# ATSAML10E16A device description
Architecture: CORTEX-M23; Family: SAML; Series: SAML10
Registers are 32-bit, read-write, reset 0x0 unless marked. A register's access mark holds for its fields unless they carry their own. Offsets are from the block's base; [hi:lo] are bit positions; {n}, {i} and the like mark numbered series; 'fields as' and 'values as' point back to an identical list; <NAME> marks a mode.

## TC — Basic Timer Counter
Instances: TC0 0x42001000, TC1 0x42001400, TC2 0x42001800
Modes: COUNT8 when TC.CTRLA.MODE=1 (8-bit Counter Mode); COUNT16 when TC.CTRLA.MODE=0 (16-bit Counter Mode); COUNT32 when TC.CTRLA.MODE=2 (32-bit Counter Mode)
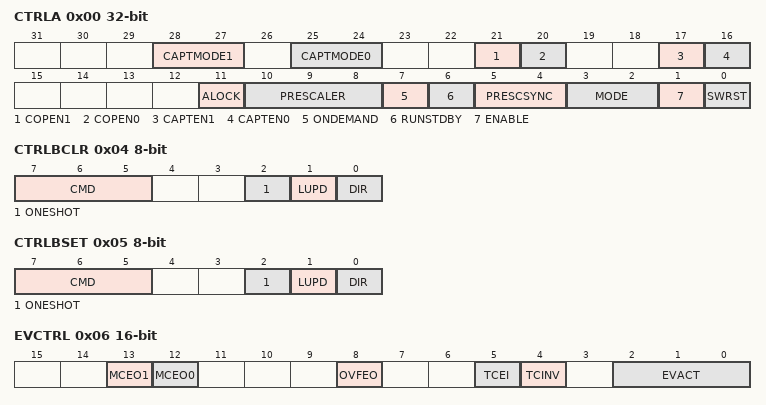
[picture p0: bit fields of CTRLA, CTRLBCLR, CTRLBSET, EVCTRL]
0x00 CTRLA — Control A
  [28:27] CAPTMODE1 — Capture mode Channel 1
    0=DEFAULT (Default capture); 1=CAPTMIN (Minimum capture); 2=CAPTMAX (Maximum capture)
  [25:24] CAPTMODE0 — Capture Mode Channel 0
    values as CAPTMODE1
  [21] COPEN1 — Capture On Pin 1 Enable
  [20] COPEN0 — Capture On Pin 0 Enable
  [17] CAPTEN1 — Capture Channel 1 Enable
  [16] CAPTEN0 — Capture Channel 0 Enable
  [11] ALOCK — Auto Lock
  [10:8] PRESCALER
    0=DIV1 (Prescaler: GCLK_TC); 1=DIV2 (Prescaler: GCLK_TC/2); 2=DIV4 (Prescaler: GCLK_TC/4); 3=DIV8 (Prescaler: GCLK_TC/8); 4=DIV16 (Prescaler: GCLK_TC/16); 5=DIV64 (Prescaler: GCLK_TC/64); 6=DIV256 (Prescaler: GCLK_TC/256); 7=DIV1024 (Prescaler: GCLK_TC/1024)
  [7] ONDEMAND — Clock On Demand
  [6] RUNSTDBY — Run during Standby
  [5:4] PRESCSYNC — Prescaler and Counter Synchronization
    0=GCLK (Reload or reset the counter on next generic clock); 1=PRESC (Reload or reset the counter on next prescaler clock); 2=RESYNC (Reload or reset the counter on next generic clock and reset the prescaler counter)
  [3:2] MODE — Timer Counter Mode
    0=COUNT16 (Counter in 16-bit mode); 1=COUNT8 (Counter in 8-bit mode); 2=COUNT32 (Counter in 32-bit mode)
  [1] ENABLE
  [0] SWRST — Software Reset
0x04 CTRLBCLR 8-bit (atomic clear) (RWSYNC) — Control B Clear
  [7:5] CMD — Command
  [2] ONESHOT — One-Shot on Counter
  [1] LUPD — Lock Update
  [0] DIR — Counter Direction
0x05 CTRLBSET 8-bit (atomic set) (RWSYNC) — Control B Set
  [7:5] CMD — Command
    0=NONE (No action); 1=RETRIGGER (Force a start, restart or retrigger); 2=STOP (Force a stop); 3=UPDATE (Force update of double-buffered register); 4=READSYNC (Force a read synchronization of COUNT)
  [2] ONESHOT — One-Shot on Counter
  [1] LUPD — Lock Update
  [0] DIR — Counter Direction
0x06 EVCTRL 16-bit — Event Control
  [13] MCEO1 — MC Event Output Enable 1
  [12] MCEO0 — MC Event Output Enable 0
  [8] OVFEO — Event Output Enable
  [5] TCEI — TC Event Enable
  [4] TCINV — TC Event Input Polarity
  [2:0] EVACT — Event Action
    0=OFF (Event action disabled); 1=RETRIGGER (Start, restart or retrigger TC on event); 2=COUNT (Count on event); 3=START (Start TC on event); 4=STAMP (Time stamp capture); 5=PPW (Period catured in CC0, pulse width in CC1); 6=PWP (Period catured in CC1, pulse width in CC0); 7=PW (Pulse width capture)
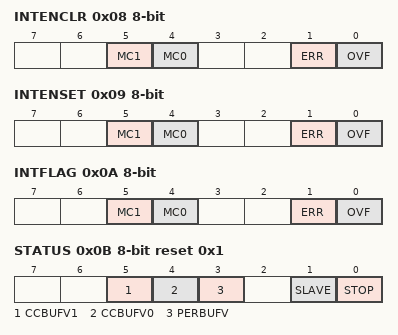
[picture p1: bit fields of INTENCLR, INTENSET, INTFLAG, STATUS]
0x08 INTENCLR 8-bit (atomic clear) — Interrupt Enable Clear
  [5] MC1 — MC Interrupt Disable 1
  [4] MC0 — MC Interrupt Disable 0
  [1] ERR — ERR Interrupt Disable
  [0] OVF — OVF Interrupt Disable
0x09 INTENSET 8-bit (atomic set) — Interrupt Enable Set
  [5] MC1 — MC Interrupt Enable 1
  [4] MC0 — MC Interrupt Enable 0
  [1] ERR — ERR Interrupt Enable
  [0] OVF — OVF Interrupt Enable
0x0A INTFLAG 8-bit (atomic clear) — Interrupt Flag Status and Clear
  [5] MC1 — MC Interrupt Flag 1
  [4] MC0 — MC Interrupt Flag 0
  [1] ERR — ERR Interrupt Flag
  [0] OVF — OVF Interrupt Flag
0x0B STATUS 8-bit reset 0x1 (RSYNC)
  [5] CCBUFV1 — Compare channel buffer 1 valid
  [4] CCBUFV0 — Compare channel buffer 0 valid
  [3] PERBUFV — Synchronization Busy Status
  [1] SLAVE — Slave Status Flag
  [0] STOP — Stop Status Flag
0x0C WAVE 8-bit — Waveform Generation Control
  [1:0] WAVEGEN — Waveform Generation Mode
    0=NFRQ (Normal frequency); 1=MFRQ (Match frequency); 2=NPWM (Normal PWM); 3=MPWM (Match PWM)
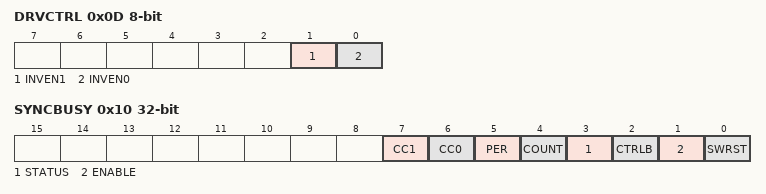
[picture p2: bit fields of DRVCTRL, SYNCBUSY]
0x0D DRVCTRL 8-bit — Control C
  [1] INVEN1 — Output Waveform Invert Enable 1
  [0] INVEN0 — Output Waveform Invert Enable 0
0x0F DBGCTRL 8-bit — Debug Control
  [0] DBGRUN — Run During Debug
0x10 SYNCBUSY ro — Synchronization Status
  [7] CC1 — Compare Channel 1
  [6] CC0 — Compare Channel 0
  [5] PER — Period
  [4] COUNT — Counter
  [3] STATUS
  [2] CTRLB
  [1] ENABLE
  [0] SWRST
0x14 COUNT <COUNT16> 16-bit (RWSYNC) — COUNT16 Count
  [15:0] COUNT — Counter Value
0x1A PER <COUNT16> 16-bit reset 0xFFFF (WSYNC) — COUNT16 Period
  [15:0] PER — Period Value
{0x1C+2i} CC[{i}] (i=0..1) <COUNT16> 16-bit (RWSYNC) — COUNT16 Compare and Capture
  [15:0] CC — Counter/Compare Value
0x2E PERBUF <COUNT16> 16-bit reset 0xFFFF (WSYNC) — COUNT16 Period Buffer
  [15:0] PERBUF — Period Buffer Value
{0x30+2i} CCBUF[{i}] (i=0..1) <COUNT16> 16-bit (WSYNC) — COUNT16 Compare and Capture Buffer
  [15:0] CCBUF — Counter/Compare Buffer Value
0x14 COUNT <COUNT32> (RWSYNC) — COUNT32 Count
  [31:0] COUNT — Counter Value
0x18 PER <COUNT32> reset 0xFFFFFFFF (WSYNC) — COUNT32 Period
  [31:0] PER — Period Value
{0x1C+4i} CC[{i}] (i=0..1) <COUNT32> (WSYNC) — COUNT32 Compare and Capture
  [31:0] CC — Counter/Compare Value
0x2C PERBUF <COUNT32> reset 0xFFFFFFFF (WSYNC) — COUNT32 Period Buffer
  [31:0] PERBUF — Period Buffer Value
{0x30+4i} CCBUF[{i}] (i=0..1) <COUNT32> (WSYNC) — COUNT32 Compare and Capture Buffer
  [31:0] CCBUF — Counter/Compare Buffer Value
0x14 COUNT <COUNT8> 8-bit (RWSYNC) — COUNT8 Count
  [7:0] COUNT — Counter Value
0x1B PER <COUNT8> 8-bit reset 0xFF (WSYNC) — COUNT8 Period
  [7:0] PER — Period Value
{0x1C+i} CC[{i}] (i=0..1) <COUNT8> 8-bit (RWSYNC) — COUNT8 Compare and Capture
  [7:0] CC — Counter/Compare Value
0x2F PERBUF <COUNT8> 8-bit reset 0xFF (WSYNC) — COUNT8 Period Buffer
  [7:0] PERBUF — Period Buffer Value
{0x30+i} CCBUF[{i}] (i=0..1) <COUNT8> 8-bit (WSYNC) — COUNT8 Compare and Capture Buffer
  [7:0] CCBUF — Counter/Compare Buffer Value

## Notices in the file
Copyright (c) 2019 Microchip Technology Inc.
SPDX-License-Identifier: Apache-2.0
Licensed under the Apache License, Version 2.0 (the "License");
you may not use this file except in compliance with the License.
You may obtain a copy of the License at
http://www.apache.org/licenses/LICENSE-2.0
Unless required by applicable law or agreed to in writing, software
distributed under the License is distributed on an "AS IS" BASIS,
WITHOUT WARRANTIES OR CONDITIONS OF ANY KIND, either express or implied.
See the License for the specific language governing permissions and
limitations under the License.
